VERSION ""

NS_ :

BS_:

BU_: XXX

BO_ 85 CID_RMUIKQ: 8 XXX
 SG_ sig_ylvmdj : 40|1@1+ (1,0) [0|1] "" XXX
 SG_ sig_zqklcg : 56|8@1+ (1,0) [0|255] "" XXX

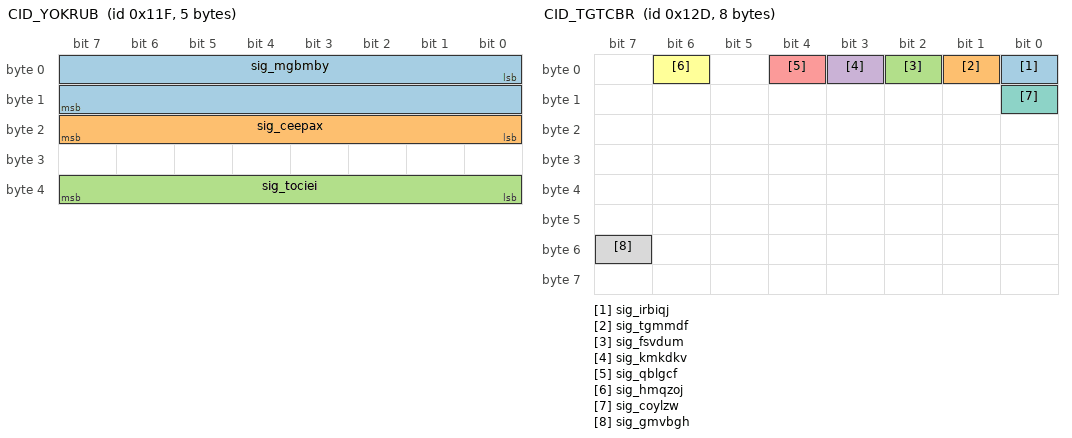
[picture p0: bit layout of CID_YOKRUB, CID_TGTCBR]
BO_ 287 CID_YOKRUB: 5 XXX
 SG_ sig_mgbmby : 0|16@1- (0.1,0) [-450|450] "" XXX
 SG_ sig_ceepax : 16|8@1+ (4,0) [0|1020] "" XXX
 SG_ sig_tociei : 32|8@1+ (1,0) [0|255] "" XXX

BO_ 289 CID_YWDLOF: 8 XXX
 SG_ sig_fzrpub : 0|12@1+ (1,0) [0|255] "" XXX

BO_ 301 CID_TGTCBR: 8 XXX
 SG_ sig_irbiqj : 0|1@0+ (1,0) [0|1] "" XXX
 SG_ sig_tgmmdf : 1|1@0+ (1,0) [0|1] "" XXX
 SG_ sig_fsvdum : 2|1@0+ (1,0) [0|1] "" XXX
 SG_ sig_kmkdkv : 3|1@0+ (1,0) [0|1] "" XXX
 SG_ sig_qblgcf : 4|1@0+ (1,0) [0|1] "" XXX
 SG_ sig_hmqzoj : 6|1@0+ (1,0) [0|1] "" XXX
 SG_ sig_coylzw : 8|1@0+ (1,0) [0|1] "" XXX
 SG_ sig_gmvbgh : 55|1@0+ (1,0) [0|1] "" XXX

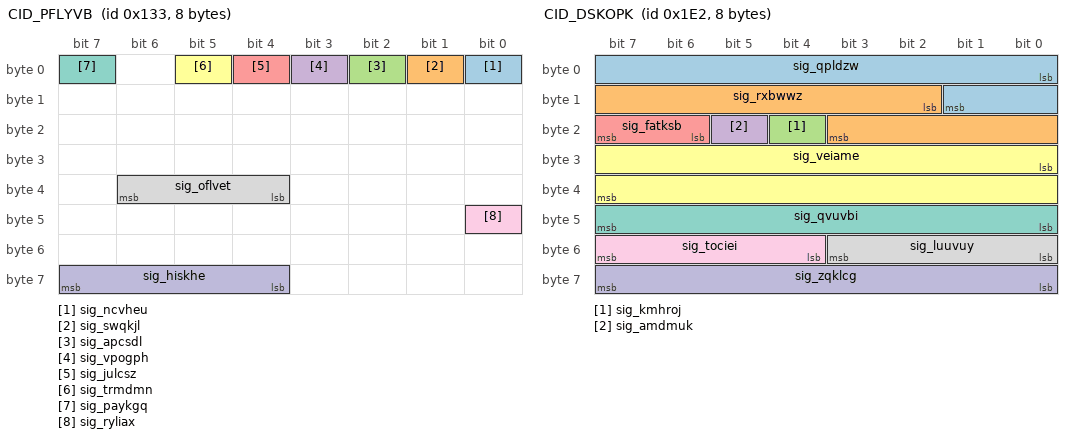
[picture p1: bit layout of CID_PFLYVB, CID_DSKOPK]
BO_ 307 CID_PFLYVB: 8 XXX
 SG_ sig_ncvheu : 0|1@0+ (1,0) [0|1] "" XXX
 SG_ sig_swqkjl : 1|1@1+ (1,0) [0|1] "" XXX
 SG_ sig_apcsdl : 2|1@1+ (1,0) [0|1] "" XXX
 SG_ sig_vpogph : 3|1@1+ (1,0) [0|1] "" XXX
 SG_ sig_julcsz : 4|1@0+ (1,0) [0|1] "" XXX
 SG_ sig_trmdmn : 5|1@0+ (1,0) [0|1] "" XXX
 SG_ sig_paykgq : 7|1@0+ (1,0) [0|1] "" XXX
 SG_ sig_oflvet : 36|3@1+ (1,0) [0|7] "" XXX
 SG_ sig_ryliax : 40|1@0+ (1,0) [0|1] "" XXX
 SG_ sig_hiskhe : 63|4@0+ (1,0) [0|15] "" XXX

BO_ 482 CID_DSKOPK: 8 XXX
 SG_ sig_qpldzw : 0|10@1- (0.01,0) [0|5] "" XXX
 SG_ sig_rxbwwz : 10|10@1- (0.01,0) [-5|0] "" XXX
 SG_ sig_kmhroj : 20|1@0+ (1,0) [0|1] "" XXX
 SG_ sig_amdmuk : 21|1@0+ (1,0) [0|1] "" XXX
 SG_ sig_fatksb : 22|2@1+ (1,0) [0|1] "" XXX
 SG_ sig_veiame : 24|16@1- (0.1,0) [-780|779.9] "" XXX
 SG_ sig_qvuvbi : 47|8@0+ (1,0) [0|255] "" XXX
 SG_ sig_luuvuy : 48|4@1+ (1,0) [0|15] "" XXX
 SG_ sig_tociei : 52|4@1+ (1,0) [0|15] "" XXX
 SG_ sig_zqklcg : 56|8@1+ (1,0) [0|255] "" XXX

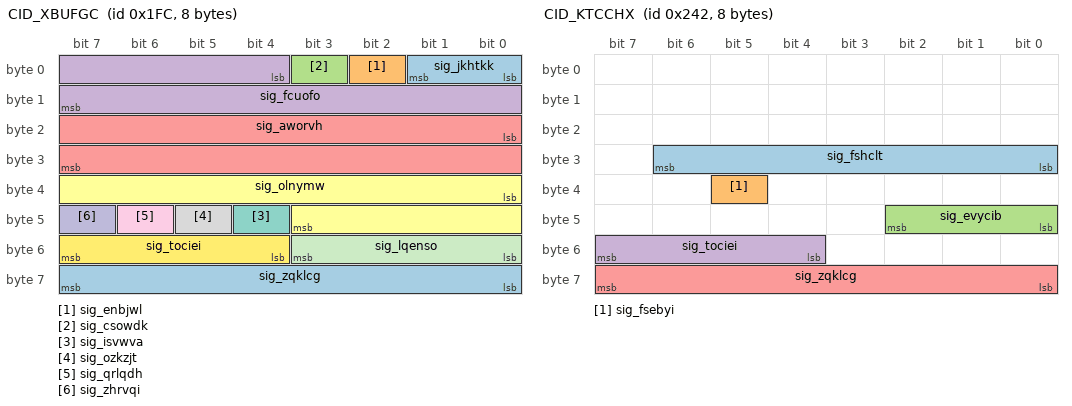
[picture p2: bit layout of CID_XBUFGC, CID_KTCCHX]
BO_ 508 CID_XBUFGC: 8 XXX
 SG_ sig_jkhtkk : 0|2@1+ (1,0) [0|1] "" XXX
 SG_ sig_enbjwl : 2|1@1+ (1,0) [0|1] "" XXX
 SG_ sig_csowdk : 3|1@0+ (1,0) [0|1] "" XXX
 SG_ sig_fcuofo : 4|12@1- (1,0) [-2048|2047] "" XXX
 SG_ sig_aworvh : 16|16@1- (0.1,0) [-780|779.9] "Deg" XXX
 SG_ sig_olnymw : 32|12@1- (0.01,0) [0|63] "" XXX
 SG_ sig_isvwva : 44|1@0+ (1,0) [0|1] "" XXX
 SG_ sig_ozkzjt : 45|1@1+ (1,0) [0|255] "" XXX
 SG_ sig_qrlqdh : 46|1@1+ (1,0) [0|1] "" XXX
 SG_ sig_zhrvqi : 47|1@0+ (1,0) [0|3] "" XXX
 SG_ sig_lqenso : 48|4@1+ (1,0) [0|15] "" XXX
 SG_ sig_tociei : 52|4@1+ (1,0) [0|15] "" XXX
 SG_ sig_zqklcg : 56|8@1+ (1,0) [0|255] "" XXX

BO_ 578 CID_KTCCHX: 8 XXX
 SG_ sig_fshclt : 30|7@0+ (1,0) [0|127] "" XXX
 SG_ sig_fsebyi : 37|1@0+ (1,0) [0|1] "" XXX
 SG_ sig_evycib : 40|3@1+ (1,0) [0|7] "" XXX
 SG_ sig_tociei : 55|4@0+ (1,0) [0|15] "" XXX
 SG_ sig_zqklcg : 56|8@1+ (1,0) [0|255] "" XXX

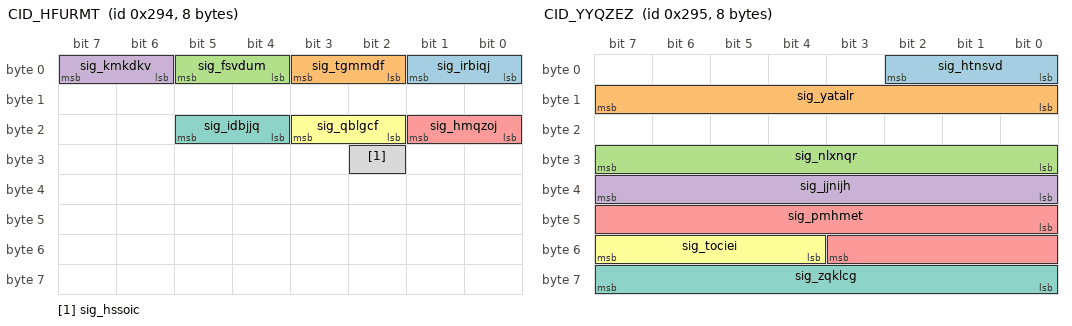
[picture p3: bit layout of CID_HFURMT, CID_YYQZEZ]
BO_ 660 CID_HFURMT: 8 XXX
 SG_ sig_irbiqj : 1|2@0+ (1,0) [0|3] "" XXX
 SG_ sig_tgmmdf : 3|2@0+ (1,0) [0|3] "" XXX
 SG_ sig_fsvdum : 5|2@0+ (1,0) [0|3] "" XXX
 SG_ sig_kmkdkv : 7|2@0+ (1,0) [0|3] "" XXX
 SG_ sig_hmqzoj : 17|2@0+ (1,0) [0|3] "" XXX
 SG_ sig_qblgcf : 19|2@0+ (1,0) [0|3] "" XXX
 SG_ sig_idbjjq : 21|2@0+ (1,0) [0|3] "" XXX
 SG_ sig_hssoic : 26|1@0+ (1,0) [0|1] "" XXX

BO_ 661 CID_YYQZEZ: 8 XXX
 SG_ sig_htnsvd : 2|3@0+ (1,0) [0|7] "" XXX
 SG_ sig_yatalr : 15|8@0+ (1,0) [0|255] "" XXX
 SG_ sig_nlxnqr : 31|8@0+ (1,0) [0|255] "" XXX
 SG_ sig_jjnijh : 32|8@1+ (1,0) [0|255] "" XXX
 SG_ sig_pmhmet : 40|12@1+ (1,0) [0|255] "" XXX
 SG_ sig_tociei : 52|4@1+ (1,0) [0|15] "" XXX
 SG_ sig_zqklcg : 63|8@0+ (1,0) [0|255] "" XXX

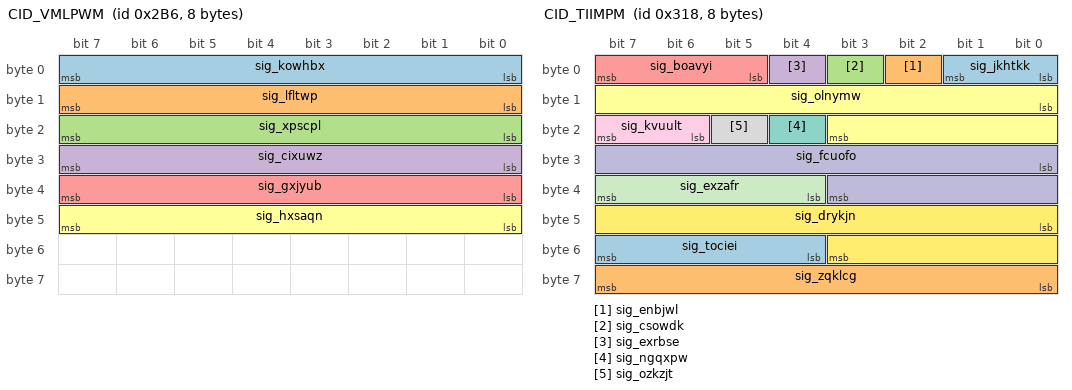
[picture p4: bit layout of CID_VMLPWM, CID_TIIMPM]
BO_ 694 CID_VMLPWM: 8 XXX
 SG_ sig_kowhbx : 7|8@0+ (1,0) [0|255] "" XXX
 SG_ sig_lfltwp : 15|8@0+ (1,0) [0|255] "" XXX
 SG_ sig_xpscpl : 23|8@0+ (1,0) [0|255] "" XXX
 SG_ sig_cixuwz : 31|8@0+ (1,0) [0|255] "" XXX
 SG_ sig_gxjyub : 39|8@0+ (1,0) [0|255] "" XXX
 SG_ sig_hxsaqn : 47|8@0+ (1,0) [0|255] "" XXX

BO_ 790 CID_WLCLWT: 8 XXX
 SG_ sig_rufdaw : 3|4@0+ (1,0) [0|1] "" XXX
 SG_ sig_vwunqg : 4|2@1+ (1,0) [0|3] "" XXX
 SG_ sig_mskofa : 6|2@1+ (1,0) [0|3] "" XXX
 SG_ sig_csecdr : 8|2@1+ (1,0) [0|3] "" XXX
 SG_ sig_cxtkco : 10|1@1+ (1,0) [0|1] "" XXX
 SG_ sig_wqiejc : 11|4@1+ (1,0) [0|1] "" XXX
 SG_ sig_yxpuji : 15|1@0+ (1,0) [0|1] "" XXX
 SG_ sig_veiame : 16|11@1- (1,0) [-1024|1023] "" XXX
 SG_ sig_kmhroj : 27|1@1+ (1,0) [0|1] "" XXX
 SG_ sig_amdmuk : 28|1@1+ (1,0) [0|3] "" XXX
 SG_ sig_txiciu : 29|1@0+ (1,0) [0|1] "" XXX
 SG_ sig_mpfxgs : 30|1@0+ (1,0) [0|1] "" XXX
 SG_ sig_ttpuao : 31|1@0+ (1,0) [0|1] "" XXX
 SG_ sig_yoihhr : 32|2@1+ (1,0) [0|3] "" XXX
 SG_ sig_xnuybo : 34|2@1+ (1,0) [0|3] "" XXX
 SG_ sig_turbgs : 36|4@1+ (1,0) [0|3] "" XXX
 SG_ sig_udzddc : 40|8@1+ (5,-5) [-5|1270] "" XXX
 SG_ sig_viafsy : 49|2@0+ (1,0) [0|3] "" XXX
 SG_ sig_rtsojm : 51|2@0+ (1,0) [0|3] "" XXX
 SG_ sig_tociei : 52|4@1+ (1,0) [0|15] "" XXX
 SG_ sig_zqklcg : 56|8@1+ (1,0) [0|15] "" XXX

BO_ 792 CID_TIIMPM: 8 XXX
 SG_ sig_jkhtkk : 0|2@1+ (1,0) [0|1] "" XXX
 SG_ sig_enbjwl : 2|1@1+ (1,0) [0|1] "" XXX
 SG_ sig_csowdk : 3|1@1+ (1,0) [0|1] "" XXX
 SG_ sig_exrbse : 4|1@1+ (1,0) [0|1] "" XXX
 SG_ sig_boavyi : 5|3@1+ (1,0) [0|1] "" XXX
 SG_ sig_olnymw : 8|12@1- (1,0) [-2048|2047] "" XXX
 SG_ sig_ngqxpw : 20|1@1+ (1,0) [0|1] "" XXX
 SG_ sig_ozkzjt : 21|1@1+ (1,0) [0|1] "" XXX
 SG_ sig_kvuult : 22|2@1+ (1,0) [0|15] "" XXX
 SG_ sig_fcuofo : 24|12@1- (1,0) [-2048|2047] "" XXX
 SG_ sig_exzafr : 36|4@1+ (1,0) [0|15] "" XXX
 SG_ sig_drykjn : 40|12@1+ (1,0) [0|4095] "" XXX
 SG_ sig_tociei : 52|4@1+ (1,0) [0|15] "" XXX
 SG_ sig_zqklcg : 56|8@1+ (1,0) [0|255] "" XXX

BO_ 813 CID_TIIWGX: 8 XXX
 SG_ sig_uyrmma : 0|9@1+ (0.5,0) [0|255.5] "" XXX
 SG_ sig_byxrhu : 9|1@1+ (1,0) [0|1] "" XXX
 SG_ sig_ddouuy : 10|3@1+ (1,0) [0|7] "" XXX
 SG_ sig_xhzdxd : 13|3@1+ (1,0) [0|7] "" XXX
 SG_ sig_huyygp : 16|1@1+ (1,0) [0|1] "" XXX
 SG_ sig_vhboqp : 17|1@1+ (1,0) [0|1] "" XXX
 SG_ sig_csowdk : 18|1@1+ (1,0) [0|1] "" XXX
 SG_ sig_biaflu : 19|3@1+ (1,0) [0|1] "" XXX
 SG_ sig_wupbjz : 22|1@0+ (1,0) [0|1] "" XXX
 SG_ sig_cretvx : 23|1@0+ (1,0) [0|1] "" XXX
 SG_ sig_csecdr : 24|1@1+ (1,0) [0|1] "" XXX
 SG_ sig_ezhcma : 25|7@1+ (1,0) [0|127] "" XXX
 SG_ sig_rfnsaf : 32|4@1+ (1,0) [0|15] "" XXX
 SG_ sig_uxjpzk : 36|12@1+ (1,0) [0|4095] "" XXX
 SG_ sig_tociei : 48|4@1+ (1,0) [0|15] "" XXX
 SG_ sig_fcjfpp : 55|4@0+ (1,0) [0|15] "" XXX
 SG_ sig_zqklcg : 56|8@1+ (1,0) [0|255] "" XXX

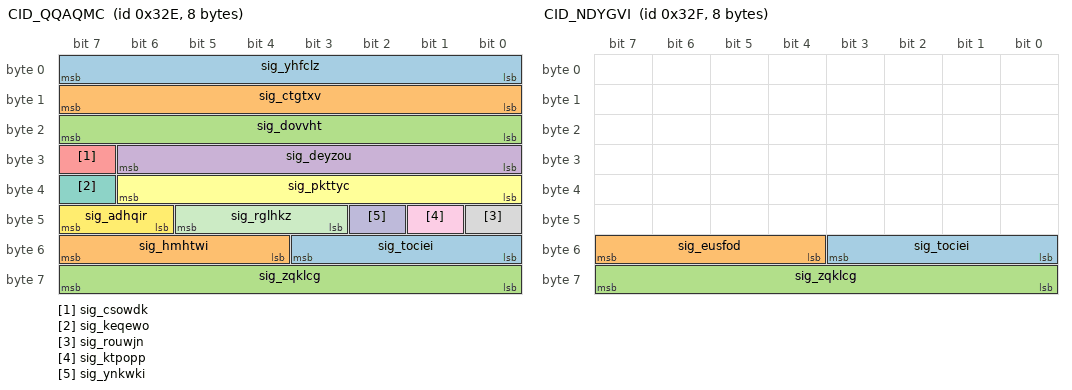
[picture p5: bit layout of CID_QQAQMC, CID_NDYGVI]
BO_ 814 CID_QQAQMC: 8 XXX
 SG_ sig_yhfclz : 0|8@1+ (0.05,-5) [-100|155] "" XXX
 SG_ sig_ctgtxv : 8|8@1+ (0.05,-5) [0|1.26] "" XXX
 SG_ sig_dovvht : 16|8@1+ (0.05,-5) [0|1.26] "" XXX
 SG_ sig_deyzou : 24|7@1+ (0.2,0) [0|12.7] "" XXX
 SG_ sig_csowdk : 31|1@0+ (1,0) [0|1] "" XXX
 SG_ sig_pkttyc : 32|7@1+ (0.2,-16) [0|12.7] "" XXX
 SG_ sig_keqewo : 39|1@0+ (1,0) [0|1] "" XXX
 SG_ sig_rouwjn : 40|1@0+ (1,0) [0|1] "" XXX
 SG_ sig_ktpopp : 41|1@0+ (1,0) [0|1] "" XXX
 SG_ sig_ynkwki : 42|1@1+ (1,0) [0|3] "" XXX
 SG_ sig_rglhkz : 45|3@0+ (1,0) [0|1] "" XXX
 SG_ sig_adhqir : 46|2@1+ (1,0) [0|3] "" XXX
 SG_ sig_tociei : 48|4@1+ (1,0) [0|15] "" XXX
 SG_ sig_hmhtwi : 55|4@0+ (1,0) [0|15] "" XXX
 SG_ sig_zqklcg : 56|8@1+ (1,0) [0|255] "" XXX

BO_ 815 CID_NDYGVI: 8 XXX
 SG_ sig_tociei : 48|4@1+ (1,0) [0|15] "" XXX
 SG_ sig_eusfod : 55|4@0+ (1,0) [0|15] "" XXX
 SG_ sig_zqklcg : 56|8@1+ (1,0) [0|255] "" XXX

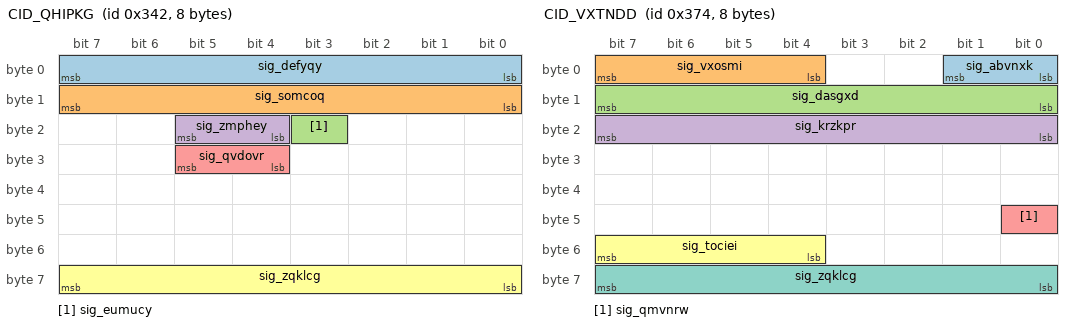
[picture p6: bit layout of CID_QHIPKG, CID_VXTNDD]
BO_ 834 CID_QHIPKG: 8 XXX
 SG_ sig_defyqy : 0|8@1+ (0.01,0) [0|2.55] "" XXX
 SG_ sig_somcoq : 8|8@1+ (0.01,0) [0|2.55] "" XXX
 SG_ sig_eumucy : 19|1@1+ (1,0) [0|1] "" XXX
 SG_ sig_zmphey : 20|2@1+ (1,0) [0|255] "" XXX
 SG_ sig_qvdovr : 28|2@1+ (1,0) [0|1] "" XXX
 SG_ sig_zqklcg : 56|8@1+ (1,0) [0|255] "" XXX

BO_ 884 CID_VXTNDD: 8 XXX
 SG_ sig_abvnxk : 1|2@0+ (1,0) [0|3] "" XXX
 SG_ sig_vxosmi : 7|4@0+ (1,0) [0|15] "" XXX
 SG_ sig_dasgxd : 15|8@0+ (0.1,-12) [0|255] "" XXX
 SG_ sig_krzkpr : 23|8@0+ (1,-100) [0|255] "" XXX
 SG_ sig_qmvnrw : 40|1@0+ (1,0) [0|3] "" XXX
 SG_ sig_tociei : 52|4@1+ (1,0) [0|15] "" XXX
 SG_ sig_zqklcg : 56|8@1+ (1,0) [0|255] "" XXX

BO_ 944 CID_HXSTEP: 8 XXX
 SG_ sig_nigbhy : 1|2@0+ (1,0) [0|3] "" XXX
 SG_ sig_eszduc : 2|1@0+ (1,0) [0|1] "" XXX
 SG_ sig_pndpmt : 4|2@0+ (1,0) [0|3] "" XXX
 SG_ sig_pnreok : 5|1@0+ (1,0) [0|1] "" XXX
 SG_ sig_uqcqsw : 6|1@0+ (1,0) [0|1] "" XXX
 SG_ sig_ugsuym : 7|1@0+ (1,0) [0|1] "" XXX
 SG_ sig_jdcqhb : 8|1@0+ (1,0) [0|1] "" XXX
 SG_ sig_ljbevd : 11|3@0+ (1,0) [0|7] "" XXX
 SG_ sig_ftnksp : 12|1@0+ (1,0) [0|1] "" XXX
 SG_ sig_xzqfil : 14|2@0+ (1,0) [0|3] "" XXX
 SG_ sig_iwcvom : 15|1@0+ (1,0) [0|1] "" XXX
 SG_ sig_ycsdfc : 16|1@0+ (1,0) [0|1] "" XXX
 SG_ sig_jzjeca : 18|2@0+ (1,0) [0|3] "" XXX
 SG_ sig_mnrnjq : 19|1@0+ (1,0) [0|1] "" XXX
 SG_ sig_edrubk : 23|4@0+ (1,0) [0|15] "" XXX
 SG_ sig_iqawxk : 24|28@1+ (1,0) [0|268435455] "" XXX
 SG_ sig_tociei : 52|4@1+ (1,0) [0|15] "" XXX
 SG_ sig_zqklcg : 56|8@1+ (1,0) [0|255] "" XXX

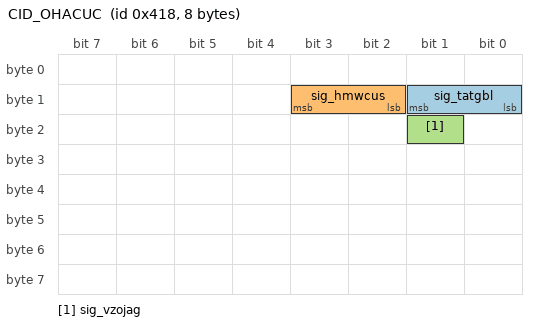
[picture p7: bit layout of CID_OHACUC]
BO_ 1048 CID_OHACUC: 8 XXX
 SG_ sig_tatgbl : 9|2@0+ (1,0) [0|1] "" XXX
 SG_ sig_hmwcus : 11|2@0+ (1,0) [0|1] "" XXX
 SG_ sig_vzojag : 17|1@0+ (1,0) [0|1] "" XXX

VAL_ 578 sig_evycib 4 "D" 2 "R" 3 "N" 1 "P";
VAL_ 790 sig_rufdaw 11 "AutoFullBeamActive" 2 "AutoFullBeamInactive";
VAL_ 790 sig_vwunqg 0 "GRAY" 1 "GREEN" 2 "YELLOW" 3 "RED";
VAL_ 790 sig_mskofa 3 "ALARM_AND_LKA" 2 "LKA" 1 "ALARM" 0 "DISABLE";
VAL_ 790 sig_xnuybo 0 "GRAY" 1 "GREEN" 2 "YELLOW" 3 "RED";
VAL_ 790 sig_viafsy 0 "VIBRATION" 1 "AUDIO" 2 "AUDIO_AND_VIBRATION";
VAL_ 792 sig_jkhtkk 0 "NotReady" 1 "Ready" 2 "Active" 3 "TemporaryFail";
VAL_ 813 sig_ddouuy 4 "4BAR" 3 "3BAR" 2 "2BAR" 1 "1BAR";
VAL_ 813 sig_biaflu 0 "OFF" 2 "ACC_ON" 3 "ACC_ACTIVE" 5 "FORCE_ACCEL" 7 "ERROR";
VAL_ 813 sig_ezhcma 36 "ACC_ERROR" 22 "OVERRIDE" 12 "ENGAGE" 8 "DISENGAGE" 20 "ACC_ON" 32 "ACC_OFF" 48 "CHECK_GEAR_D" 16 "FORCE_ACCEL" 0 "NONE";
VAL_ 814 sig_rglhkz 0 "Off" 1 "Passive" 2 "StandBy" 3 "ActiveControl" 4 "BrakeOnly" 5 "Override" 6 "Standstill" 7 "Failure";
VAL_ 814 sig_adhqir 0 "Softoff" 1 "Fastoff" 2 "Immediateoff" 3 "Initial";
VAL_ 834 sig_zmphey 2 "SPORT" 1 "ECO" 0 "SNOW";
VAL_ 834 sig_qvdovr 3 "HEV" 2 "FORCE_EV" 1 "EV";
VAL_ 944 sig_pndpmt 0 "NOTPRESSED" 1 "DOWN_SETSPEED" 3 "UP_RESETSPEED";
